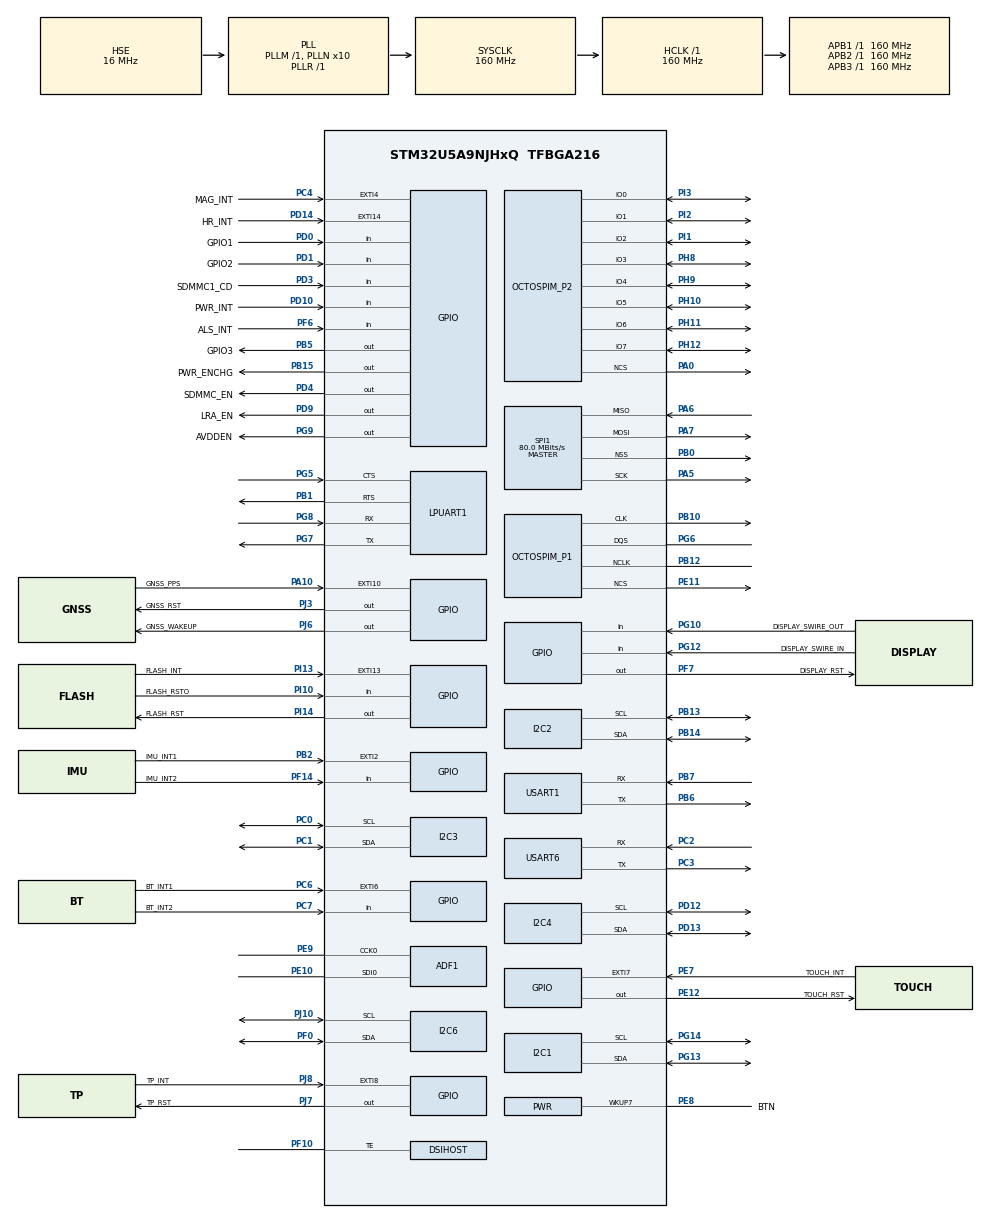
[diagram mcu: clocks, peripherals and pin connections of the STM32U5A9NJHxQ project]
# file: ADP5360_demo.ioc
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ADF1.MDF_SITF0_Mode_Display=MDF_SITF_NORMAL_SPI_MODE
CORTEX_M33_NS.userName=CORTEX_M33
DMA2D.ColorMode=DMA2D_OUTPUT_RGB888
DSIHOST.AutomaticClockLaneControl=DSI_AUTO_CLK_LANE_CTRL_DISABLE
DSIHOST.PHYFrequencyRange=DSI_DPHY_FRANGE_450MHZ_510MHZ
DSIHOST.PLLVCORange=DSI_DPHY_VCO_FRANGE_800MHZ_1GHZ
DSIHOST.StopWaitTime=10
DSI_CKN.Mode=DSIHost_Adapted_TE
DSI_CKN.Signal=DSIHOST_CKN
DSI_CKP.Mode=DSIHost_Adapted_TE
DSI_CKP.Signal=DSIHOST_CKP
DSI_D0N.Mode=DSIHost_Adapted_TE
DSI_D0N.Signal=DSIHOST_D0N
DSI_D0P.Mode=DSIHost_Adapted_TE
DSI_D0P.Signal=DSIHOST_D0P
DSI_D1N.Mode=DSIHost_Adapted_TE
DSI_D1N.Signal=DSIHOST_D1N
DSI_D1P.Mode=DSIHost_Adapted_TE
DSI_D1P.Signal=DSIHOST_D1P
I2C1.Timing=0x30909DEC
I2C2.Timing=0x30909DEC
I2C3.Timing=0x30909DEC
I2C4.Timing=0x30909DEC
I2C6.Timing=0x30909DEC
LTDC.ActiveH=416
LTDC.ActiveW=416
LTDC.Alpha_L0=255
LTDC.HBP=0
LTDC.HFP=0
LTDC.HSPolarity=LTDC_HSPOLARITY_AH
LTDC.HSync=1
LTDC.ImageHeight_L0=416
LTDC.ImageWidth_L0=416
LTDC.Layers=0
LTDC.VBP=0
LTDC.VFP=0
LTDC.VSPolarity=LTDC_VSPOLARITY_AH
LTDC.VSync=1
LTDC.WindowX1_L0=416
LTDC.WindowY1_L0=416
Mcu.Family=STM32U5
Mcu.Name=STM32U5A9NJHxQ
Mcu.Package=TFBGA216
Mcu.UserConstants=OLED_WIDTH,416;OLED_HEIGHT,416
NVIC.DMA2D_IRQn=true\:0\:0\:false\:false\:true\:true\:true\:true
NVIC.DSI_IRQn=true\:0\:0\:false\:false\:true\:true\:true\:true
NVIC.GFXMMU_IRQn=true\:0\:0\:false\:false\:true\:true\:true\:true
NVIC.GPU2D_ER_IRQn=true\:0\:0\:false\:false\:true\:false\:true\:true
NVIC.GPU2D_IRQn=true\:0\:0\:false\:false\:true\:false\:true\:true
NVIC.LTDC_IRQn=true\:0\:0\:false\:false\:true\:true\:true\:true
NVIC.PriorityGroup=NVIC_PRIORITYGROUP_4
NVIC.TIM6_IRQn=true\:15\:0\:false\:false\:true\:false\:true\:true
NVIC.TimeBase=TIM6_IRQn
NVIC.TimeBaseIP=TIM6
OCTOSPI1.ClockPrescaler=16
OCTOSPI1.DeviceSize=26
OCTOSPI1.DeviceType=SPI_DEVICE_FLASH
OCTOSPI1.MaxTran=16
OCTOSPI1.WrapSize=HAL_OSPI_WRAP_64_BYTES
PA0.Mode=OCTOSPI2_Port2_NCS
PA0.Signal=OCTOSPIM_P2_NCS
PA10.GPIO_Label=GNSS_PPS
PA10.Signal=GPXTI10
PA11.Signal=USB_OTG_HS_DM
PA12.Signal=USB_OTG_HS_DP
PA13\ (JTMS/SWDIO).Mode=Trace_Asynchronous_SW
PA13\ (JTMS/SWDIO).Signal=DEBUG_JTMS-SWDIO
PA14\ (JTCK/SWCLK).Mode=Trace_Asynchronous_SW
PA14\ (JTCK/SWCLK).Signal=DEBUG_JTCK-SWCLK
PA5.Mode=Full_Duplex_Master
PA5.Signal=SPI1_SCK
PA6.Mode=Full_Duplex_Master
PA6.Signal=SPI1_MISO
PA7.Mode=Full_Duplex_Master
PA7.Signal=SPI1_MOSI
PB0.Mode=NSS_Signal_Hard_Output
PB0.Signal=SPI1_NSS
PB1.Mode=CTS_RTS
PB1.Signal=LPUART1_RTS
PB10.Mode=O1_P1_CLK_MX
PB10.Signal=OCTOSPIM_P1_CLK
PB12.Mode=OCTOSPI1_Port1_NCLK_MX
PB12.Signal=OCTOSPIM_P1_NCLK
PB13.Mode=I2C
PB13.Signal=I2C2_SCL
PB14.Mode=I2C
PB14.Signal=I2C2_SDA
PB15.GPIO_Label=PWR_ENCHG
PB15.GPIO_PuPd=GPIO_PULLDOWN
PB15.Signal=GPIO_Output
PB2.GPIO_Label=IMU_INT1
PB2.Signal=GPXTI2
PB3\ (JTDO/TRACESWO).Mode=Trace_Asynchronous_SW
PB3\ (JTDO/TRACESWO).Signal=DEBUG_JTDO-SWO
PB5.GPIO_Label=GPIO3
PB5.GPIO_PuPd=GPIO_PULLDOWN
PB5.Signal=GPIO_Output
PB6.Mode=Asynchronous
PB6.Signal=USART1_TX
PB7.Mode=Asynchronous
PB7.Signal=USART1_RX
PB8.Signal=SDMMC1_CKIN
PC0.Mode=I2C
PC0.Signal=I2C3_SCL
PC1.Mode=I2C
PC1.Signal=I2C3_SDA
PC10.Signal=SDMMC1_D2
PC11.Signal=SDMMC1_D3
PC12.Signal=SDMMC1_CK
PC14-OSC32_IN\ (PC14).Mode=LSE-External-Oscillator
PC14-OSC32_IN\ (PC14).Signal=RCC_OSC32_IN
PC15-OSC32_OUT\ (PC15).Mode=LSE-External-Oscillator
PC15-OSC32_OUT\ (PC15).Signal=RCC_OSC32_OUT
PC2.Mode=Asynchronous
PC2.Signal=USART6_RX
PC3.Mode=Asynchronous
PC3.Signal=USART6_TX
PC4.GPIO_Label=MAG_INT
PC4.GPIO_ModeDefaultEXTI=GPIO_MODE_IT_FALLING
PC4.GPIO_PuPd=GPIO_PULLUP
PC4.Signal=GPXTI4
PC6.GPIO_Label=BT_INT1
PC6.GPIO_PuPd=GPIO_PULLDOWN
PC6.Signal=GPXTI6
PC7.GPIO_Label=BT_INT2
PC7.GPIO_PuPd=GPIO_PULLDOWN
PC7.Signal=GPIO_Input
PC8.Signal=SDMMC1_D0
PC9.Signal=SDMMC1_D1
PD0.GPIO_Label=GPIO1
PD0.GPIO_PuPd=GPIO_PULLDOWN
PD0.Signal=GPIO_Input
PD1.GPIO_Label=GPIO2
PD1.GPIO_PuPd=GPIO_PULLDOWN
PD1.Signal=GPIO_Input
PD10.GPIO_Label=PWR_INT
PD10.GPIO_PuPd=GPIO_PULLUP
PD10.Signal=GPIO_Input
PD12.Mode=I2C
PD12.Signal=I2C4_SCL
PD13.Mode=I2C
PD13.Signal=I2C4_SDA
PD14.GPIO_Label=HR_INT
PD14.GPIO_ModeDefaultEXTI=GPIO_MODE_IT_FALLING
PD14.GPIO_PuPd=GPIO_PULLUP
PD14.Signal=GPXTI14
PD2.Signal=SDMMC1_CMD
PD3.GPIO_Label=SDMMC1_CD
PD3.GPIO_PuPd=GPIO_PULLUP
PD3.Signal=GPIO_Input
PD4.GPIO_Label=SDMMC_EN
PD4.GPIO_ModeDefaultOutputPP=GPIO_MODE_OUTPUT_PP
PD4.GPIO_PuPd=GPIO_NOPULL
PD4.Signal=GPIO_Output
PD9.GPIO_Label=LRA_EN
PD9.GPIO_PuPd=GPIO_PULLDOWN
PD9.Signal=GPIO_Output
PE10.Mode=MOD_ADF_CCK
PE10.Signal=ADF1_SDI0
PE11.Mode=OCTOSPI1_Port1_NCS
PE11.Signal=OCTOSPIM_P1_NCS
PE12.GPIO_Label=TOUCH_RST
PE12.GPIO_PuPd=GPIO_PULLUP
PE12.Signal=GPIO_Output
PE7.GPIO_Label=TOUCH_INT
PE7.GPIO_ModeDefaultEXTI=GPIO_MODE_IT_FALLING
PE7.GPIO_PuPd=GPIO_PULLUP
PE7.Signal=GPXTI7
PE8.GPIO_Label=BTN
PE8.Mode=WakeUp7
PE8.Signal=PWR_WKUP7
PE9.Mode=MOD_MDF_CCK0
PE9.Signal=ADF1_CCK0
PF0.Mode=I2C
PF0.Signal=I2C6_SDA
PF10.Mode=DSIHost_Adapted_TE
PF10.Signal=DSIHOST_TE
PF14.GPIO_Label=IMU_INT2
PF14.Signal=GPIO_Input
PF6.GPIO_Label=ALS_INT
PF6.GPIO_PuPd=GPIO_PULLUP
PF6.Signal=GPIO_Input
PF7.GPIO_Label=DISPLAY_RST
PF7.GPIO_PuPd=GPIO_PULLUP
PF7.Signal=GPIO_Output
PG10.GPIO_Label=DISPLAY_SWIRE_OUT
PG10.Signal=GPIO_Input
PG12.GPIO_Label=DISPLAY_SWIRE_IN
PG12.Signal=GPIO_Input
PG13.Mode=I2C
PG13.Signal=I2C1_SDA
PG14.Mode=I2C
PG14.Signal=I2C1_SCL
PG5.Mode=CTS_RTS
PG5.Signal=LPUART1_CTS
PG6.Mode=OCTOSPI1_Port1_DQS_MX
PG6.Signal=OCTOSPIM_P1_DQS
PG7.Mode=Asynchronous
PG7.Signal=LPUART1_TX
PG8.Mode=Asynchronous
PG8.Signal=LPUART1_RX
PG9.GPIO_Label=AVDDEN
PG9.GPIO_PuPd=GPIO_PULLDOWN
PG9.Signal=GPIO_Output
PH0-OSC_IN\ (PH0).Mode=HSE-External-Oscillator
PH0-OSC_IN\ (PH0).Signal=RCC_OSC_IN
PH1-OSC_OUT\ (PH1).Mode=HSE-External-Oscillator
PH1-OSC_OUT\ (PH1).Signal=RCC_OSC_OUT
PH10.Mode=OCTOSPI1_IOH_Port2H_74_MX
PH10.Signal=OCTOSPIM_P2_IO5
PH11.Mode=OCTOSPI1_IOH_Port2H_74_MX
PH11.Signal=OCTOSPIM_P2_IO6
PH12.Mode=OCTOSPI1_IOH_Port2H_74_MX
PH12.Signal=OCTOSPIM_P2_IO7
PH8.Mode=OCTOSPI1_IOL_Port2L_30_MX
PH8.Signal=OCTOSPIM_P2_IO3
PH9.Mode=OCTOSPI1_IOH_Port2H_74_MX
PH9.Signal=OCTOSPIM_P2_IO4
PI1.Mode=OCTOSPI1_IOL_Port2L_30_MX
PI1.Signal=OCTOSPIM_P2_IO2
PI10.GPIO_Label=FLASH_RSTO
PI10.GPIO_PuPd=GPIO_PULLUP
PI10.Signal=GPIO_Input
PI13.GPIO_Label=FLASH_INT
PI13.GPIO_ModeDefaultEXTI=GPIO_MODE_IT_FALLING
PI13.GPIO_PuPd=GPIO_PULLUP
PI13.Signal=GPXTI13
PI14.GPIO_Label=FLASH_RST
PI14.GPIO_PuPd=GPIO_PULLUP
PI14.Signal=GPIO_Output
PI2.Mode=OCTOSPI1_IOL_Port2L_30_MX
PI2.Signal=OCTOSPIM_P2_IO1
PI3.Mode=OCTOSPI1_IOL_Port2L_30_MX
PI3.Signal=OCTOSPIM_P2_IO0
PJ10.Mode=I2C
PJ10.Signal=I2C6_SCL
PJ3.GPIO_Label=GNSS_RST
PJ3.GPIO_PuPd=GPIO_PULLUP
PJ3.Signal=GPIO_Output
PJ6.GPIO_Label=GNSS_WAKEUP
PJ6.Signal=GPIO_Output
PJ7.GPIO_Label=TP_RST
PJ7.GPIO_PuPd=GPIO_PULLUP
PJ7.Signal=GPIO_Output
PJ8.GPIO_Label=TP_INT
PJ8.GPIO_ModeDefaultEXTI=GPIO_MODE_IT_FALLING
PJ8.GPIO_PuPd=GPIO_PULLUP
PJ8.Signal=GPXTI8
PWR.PowerMode=PWR_SMPS_SUPPLY
ProjectManager.HeapSize=0x200
ProjectManager.StackSize=0x400
ProjectManager.TargetToolchain=STM32CubeIDE
RCC.ADCFreq_Value=16000000
RCC.AHBFreq_Value=160000000
RCC.APB1Freq_Value=160000000
RCC.APB1TimFreq_Value=160000000
RCC.APB2Freq_Value=160000000
RCC.APB2TimFreq_Value=160000000
RCC.APB3Freq_Value=160000000
RCC.CortexFreq_Value=160000000
RCC.EPOD_VALUE=16000000
RCC.EnableCSSLSE=true
RCC.EnbaleCSS=true
RCC.HCLKFreq_Value=160000000
RCC.HSE_VALUE=16000000
RCC.HSI48_VALUE=48000000
RCC.HSI_VALUE=16000000
RCC.LSIDIV_VALUE=32000
RCC.MSIClockRange=RCC_MSIRANGE_0
RCC.MSI_VALUE=48000000
RCC.PLL1R=1
RCC.PLL2N=20
RCC.PLL2Source=RCC_PLLSOURCE_HSE
RCC.PLL3N=10
RCC.PLL3Source=RCC_PLLSOURCE_HSE
RCC.PLLDSIIDF=DSI_PLL_IN_DIV4
RCC.PLLDSINDIV=125
RCC.PLLDSIODF=DSI_PLL_OUT_DIV2
RCC.PLLFRACN=0
RCC.PLLN=10
RCC.PLLSourceVirtual=RCC_PLLSOURCE_HSE
RCC.RTCClockSelection=RCC_RTCCLKSOURCE_LSE
RCC.SYSCLKFreq_VALUE=160000000
RCC.SYSCLKSource=RCC_SYSCLKSOURCE_PLLCLK
RCC.USBPHYCLockSelection=RCC_USBPHYCLKSOURCE_HSE
RCC.VCOOutputFreq_Value=160000000
RCC.VDD_VALUE=1.8
RTC.Date=1
SPI1.CalculateBaudRate=80.0 MBits/s
SPI1.Direction=SPI_DIRECTION_2LINES
SPI1.Mode=SPI_MODE_MASTER
SPI1.VirtualNSS=VM_NSSHARD
SPI1.VirtualType=VM_MASTER
STMicroelectronics.X-CUBE-TOUCHGFX.4.23.0.tgfx_custom_height=416
STMicroelectronics.X-CUBE-TOUCHGFX.4.23.0.tgfx_display_interface=disp_ltdc
STMicroelectronics.X-CUBE-TOUCHGFX.4.23.0.tgfx_hardware_accelerator=dma_2d
STMicroelectronics.X-CUBE-TOUCHGFX.4.23.0.tgfx_nemap_accelerator=gpu2d_enabled
STMicroelectronics.X-CUBE-TOUCHGFX.4.23.0.tgfx_pixel_format=ARGB8888\:32
STMicroelectronics.X-CUBE-TOUCHGFX.4.23.0_IsPackSelfContextualization=true
USART1.VirtualMode-Asynchronous=VM_ASYNC
USART6.VirtualMode-Asynchronous=VM_ASYNC
VP_CRC_VS_CRC.Mode=CRC_Activate
VP_DCACHE1_VS_DCACHE.Mode=DCACHE_Activate
VP_DCACHE2_VS_DCACHE.Mode=DCACHE_Activate
VP_DMA2D_VS_DMA2D.Mode=DMA2D_Activate
VP_GFXMMU_VS_GFXMMU.Mode=GFXMMU_Activate
VP_GPU2D_VS_GPU2D.Mode=GPU2D_Activate
VP_ICACHE_VS_ENABLE_ICACHE_MEMORY.Mode=Memoryregions
VP_ICACHE_VS_ICACHE.Mode=DefaultMode
VP_LPBAMQUEUE_VS_QUEUE.Mode=QUEUEMODE
VP_LPBAM_VS_SIG1.Mode=SmartRun
VP_LPBAM_VS_SIG4.Mode=LPDMA1
VP_LTDC_DSIMode.Mode=RGB888
VP_MEMORYMAP_VS_MEMORYMAP.Mode=CurAppReg
VP_OCTOSPI1_VS_hyperbus_mx.Mode=hyperbus_mode_mx
VP_OCTOSPI2_VS_hyperbus_mx.Mode=hyperbus_mode_mx
VP_OCTOSPI2_VS_ospi2_mx_p1_clk.Mode=O2_P1_CLK_MX
VP_OCTOSPI2_VS_ospi2_mx_p1_dqs.Mode=OCTOSPI2_Port1_DQS_MX
VP_OCTOSPI2_VS_ospi2_mx_p1_nclk.Mode=OCTOSPI2_Port1_NCLK_MX
VP_OCTOSPI2_VS_ospi2_mx_p2_30.Mode=OCTOSPI2_IOL_Port2L_30_MX
VP_OCTOSPI2_VS_ospi2_mx_p2_74.Mode=OCTOSPI2_IOH_Port2H_74_MX
VP_PWR_VS_LPOM.Mode=PowerOptimisation
VP_PWR_VS_SECSignals.Mode=Security/Privilege
VP_RTC_VS_RTC_Activate.Mode=RTC_Enabled
VP_RTC_VS_RTC_Calendar.Mode=RTC_Calendar
VP_SYS_VS_tim6.Mode=TIM6
board=custom

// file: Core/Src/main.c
/* USER CODE BEGIN Header */
/**
  ******************************************************************************
  * @file           : main.c
  * @brief          : Main program body
  ******************************************************************************
  * @attention
  *
  * Copyright (c) 2024 STMicroelectronics.
  * All rights reserved.
  *
  * This software is licensed under terms that can be found in the LICENSE file
  * in the root directory of this software component.
  * If no LICENSE file comes with this software, it is provided AS-IS.
  *
  ******************************************************************************
  */
/* USER CODE END Header */
#include "main.h"
#include "gfxmmu_lut.h"

/* USER CODE BEGIN Includes */
#include "ADP5360.h"
/* USER CODE END Includes */

MDF_HandleTypeDef AdfHandle0;
MDF_FilterConfigTypeDef AdfFilterConfig0;

CRC_HandleTypeDef hcrc;

DCACHE_HandleTypeDef hdcache1;
DCACHE_HandleTypeDef hdcache2;

DMA2D_HandleTypeDef hdma2d;

DSI_HandleTypeDef hdsi;

GFXMMU_HandleTypeDef hgfxmmu;

GPU2D_HandleTypeDef hgpu2d;

I2C_HandleTypeDef hi2c1;
I2C_HandleTypeDef hi2c2;
I2C_HandleTypeDef hi2c3;
I2C_HandleTypeDef hi2c4;
I2C_HandleTypeDef hi2c6;

UART_HandleTypeDef hlpuart1;
UART_HandleTypeDef huart1;
UART_HandleTypeDef huart6;

LTDC_HandleTypeDef hltdc;

OSPI_HandleTypeDef hospi1;
OSPI_HandleTypeDef hospi2;

RTC_HandleTypeDef hrtc;

SPI_HandleTypeDef hspi1;

/* USER CODE BEGIN PV */

ADP5360_HandleTypeDef hadp5360;

/* USER CODE END PV */

void SystemClock_Config(void);
static void SystemPower_Config(void);
static void MX_GPIO_Init(void);
static void MX_DCACHE1_Init(void);
static void MX_DCACHE2_Init(void);
static void MX_ICACHE_Init(void);
static void MX_LPUART1_UART_Init(void);
static void MX_OCTOSPI1_Init(void);
static void MX_CRC_Init(void);
static void MX_DMA2D_Init(void);
static void MX_DSIHOST_DSI_Init(void);
static void MX_GFXMMU_Init(void);
static void MX_GPU2D_Init(void);
static void MX_LTDC_Init(void);
static void MX_RTC_Init(void);
static void MX_OCTOSPI2_Init(void);
static void MX_ADF1_Init(void);
static void MX_I2C1_Init(void);
static void MX_I2C2_Init(void);
static void MX_I2C4_Init(void);
static void MX_I2C6_Init(void);
static void MX_USART1_UART_Init(void);
static void MX_USART6_UART_Init(void);
static void MX_SPI1_Init(void);
static void MX_I2C3_Init(void);

int main(void)
{

  /* MCU Configuration--------------------------------------------------------*/

  /* Reset of all peripherals, Initializes the Flash interface and the Systick. */
  HAL_Init();

  /* Configure the system clock */
  SystemClock_Config();

  /* Configure the System Power */
  SystemPower_Config();

  /* Initialize all configured peripherals */
  MX_GPIO_Init();
  MX_DCACHE1_Init();
  MX_DCACHE2_Init();
  MX_ICACHE_Init();
  MX_LPUART1_UART_Init();
  MX_OCTOSPI1_Init();
  MX_CRC_Init();
  MX_DMA2D_Init();
  MX_DSIHOST_DSI_Init();
  MX_GFXMMU_Init();
  MX_GPU2D_Init();
  MX_LTDC_Init();
  MX_RTC_Init();
  MX_OCTOSPI2_Init();
  MX_ADF1_Init();
  MX_I2C1_Init();
  MX_I2C2_Init();
  MX_I2C4_Init();
  MX_I2C6_Init();
  MX_USART1_UART_Init();
  MX_USART6_UART_Init();
  MX_SPI1_Init();
  MX_I2C3_Init();

  /* USER CODE BEGIN 2 */
  ADP5360_Init(&hadp5360, &hi2c2);
  ADP5360_EnableMRShipmentMode(&hadp5360);
  ADP5360_EnableBuckBoost(&hadp5360);
  /* USER CODE END 2 */

  /* Infinite loop */
  while (1)
  {

  }
}

void SystemClock_Config(void)
{
  RCC_OscInitTypeDef RCC_OscInitStruct = {0};
  RCC_ClkInitTypeDef RCC_ClkInitStruct = {0};

  /** Configure the main internal regulator output voltage
  */
  if (HAL_PWREx_ControlVoltageScaling(PWR_REGULATOR_VOLTAGE_SCALE1) != HAL_OK)
  {
    Error_Handler();
  }

  /** Configure LSE Drive Capability
  */
  HAL_PWR_EnableBkUpAccess();
  __HAL_RCC_LSEDRIVE_CONFIG(RCC_LSEDRIVE_LOW);

  /** Initializes the CPU, AHB and APB buses clocks
  */
  RCC_OscInitStruct.OscillatorType = RCC_OSCILLATORTYPE_HSE|RCC_OSCILLATORTYPE_LSE;
  RCC_OscInitStruct.HSEState = RCC_HSE_ON;
  RCC_OscInitStruct.LSEState = RCC_LSE_ON;
  RCC_OscInitStruct.PLL.PLLState = RCC_PLL_ON;
  RCC_OscInitStruct.PLL.PLLSource = RCC_PLLSOURCE_HSE;
  RCC_OscInitStruct.PLL.PLLMBOOST = RCC_PLLMBOOST_DIV1;
  RCC_OscInitStruct.PLL.PLLM = 1;
  RCC_OscInitStruct.PLL.PLLN = 10;
  RCC_OscInitStruct.PLL.PLLP = 2;
  RCC_OscInitStruct.PLL.PLLQ = 2;
  RCC_OscInitStruct.PLL.PLLR = 1;
  RCC_OscInitStruct.PLL.PLLRGE = RCC_PLLVCIRANGE_1;
  RCC_OscInitStruct.PLL.PLLFRACN = 0;
  if (HAL_RCC_OscConfig(&RCC_OscInitStruct) != HAL_OK)
  {
    Error_Handler();
  }

  /** Initializes the CPU, AHB and APB buses clocks
  */
  RCC_ClkInitStruct.ClockType = RCC_CLOCKTYPE_HCLK|RCC_CLOCKTYPE_SYSCLK
                              |RCC_CLOCKTYPE_PCLK1|RCC_CLOCKTYPE_PCLK2
                              |RCC_CLOCKTYPE_PCLK3;
  RCC_ClkInitStruct.SYSCLKSource = RCC_SYSCLKSOURCE_PLLCLK;
  RCC_ClkInitStruct.AHBCLKDivider = RCC_SYSCLK_DIV1;
  RCC_ClkInitStruct.APB1CLKDivider = RCC_HCLK_DIV1;
  RCC_ClkInitStruct.APB2CLKDivider = RCC_HCLK_DIV1;
  RCC_ClkInitStruct.APB3CLKDivider = RCC_HCLK_DIV1;

  if (HAL_RCC_ClockConfig(&RCC_ClkInitStruct, FLASH_LATENCY_4) != HAL_OK)
  {
    Error_Handler();
  }

  /** Enables the Clock Security System
  */
  HAL_RCC_EnableCSS();

  /** Enables the Clock Security System
  */
  HAL_RCCEx_EnableLSECSS();
}

/**
  * @brief Power Configuration
  * @retval None
  */
static void SystemPower_Config(void)
{
  HAL_PWREx_EnableVddIO2();

  /*
   * Switch to SMPS regulator instead of LDO
   */
  if (HAL_PWREx_ConfigSupply(PWR_SMPS_SUPPLY) != HAL_OK)
  {
    Error_Handler();
  }
}

static void MX_ADF1_Init(void)
{

  /**
    AdfHandle0 structure initialization and HAL_MDF_Init function call
  */
  AdfHandle0.Instance = ADF1_Filter0;
  AdfHandle0.Init.CommonParam.ProcClockDivider = 1;
  AdfHandle0.Init.CommonParam.OutputClock.Activation = DISABLE;
  AdfHandle0.Init.SerialInterface.Activation = ENABLE;
  AdfHandle0.Init.SerialInterface.Mode = MDF_SITF_NORMAL_SPI_MODE;
  AdfHandle0.Init.SerialInterface.ClockSource = MDF_SITF_CCK0_SOURCE;
  AdfHandle0.Init.SerialInterface.Threshold = 4;
  AdfHandle0.Init.FilterBistream = MDF_BITSTREAM0_FALLING;
  if (HAL_MDF_Init(&AdfHandle0) != HAL_OK)
  {
    Error_Handler();
  }

  /**
    AdfFilterConfig0 structure initialization

    WARNING : only structure is filled, no specific init function call for filter
  */
  AdfFilterConfig0.DataSource = MDF_DATA_SOURCE_BSMX;
  AdfFilterConfig0.Delay = 0;
  AdfFilterConfig0.CicMode = MDF_ONE_FILTER_SINC4;
  AdfFilterConfig0.DecimationRatio = 2;
  AdfFilterConfig0.Gain = 0;
  AdfFilterConfig0.ReshapeFilter.Activation = DISABLE;
  AdfFilterConfig0.HighPassFilter.Activation = DISABLE;
  AdfFilterConfig0.SoundActivity.Activation = DISABLE;
  AdfFilterConfig0.AcquisitionMode = MDF_MODE_ASYNC_CONT;
  AdfFilterConfig0.FifoThreshold = MDF_FIFO_THRESHOLD_NOT_EMPTY;
  AdfFilterConfig0.DiscardSamples = 0;

}

static void MX_CRC_Init(void)
{

  hcrc.Instance = CRC;
  hcrc.Init.DefaultPolynomialUse = DEFAULT_POLYNOMIAL_ENABLE;
  hcrc.Init.DefaultInitValueUse = DEFAULT_INIT_VALUE_ENABLE;
  hcrc.Init.InputDataInversionMode = CRC_INPUTDATA_INVERSION_NONE;
  hcrc.Init.OutputDataInversionMode = CRC_OUTPUTDATA_INVERSION_DISABLE;
  hcrc.InputDataFormat = CRC_INPUTDATA_FORMAT_BYTES;
  if (HAL_CRC_Init(&hcrc) != HAL_OK)
  {
    Error_Handler();
  }

}

static void MX_DCACHE1_Init(void)
{

  hdcache1.Instance = DCACHE1;
  hdcache1.Init.ReadBurstType = DCACHE_READ_BURST_WRAP;
  if (HAL_DCACHE_Init(&hdcache1) != HAL_OK)
  {
    Error_Handler();
  }

}

static void MX_DCACHE2_Init(void)
{

  hdcache2.Instance = DCACHE2;
  hdcache2.Init.ReadBurstType = DCACHE_READ_BURST_WRAP;
  if (HAL_DCACHE_Init(&hdcache2) != HAL_OK)
  {
    Error_Handler();
  }

}

static void MX_DMA2D_Init(void)
{

  hdma2d.Instance = DMA2D;
  hdma2d.Init.Mode = DMA2D_M2M;
  hdma2d.Init.ColorMode = DMA2D_OUTPUT_RGB888;
  hdma2d.Init.OutputOffset = 0;
  hdma2d.Init.BytesSwap = DMA2D_BYTES_REGULAR;
  hdma2d.Init.LineOffsetMode = DMA2D_LOM_PIXELS;
  hdma2d.LayerCfg[1].InputOffset = 0;
  hdma2d.LayerCfg[1].InputColorMode = DMA2D_INPUT_RGB888;
  hdma2d.LayerCfg[1].AlphaMode = DMA2D_NO_MODIF_ALPHA;
  hdma2d.LayerCfg[1].InputAlpha = 0;
  hdma2d.LayerCfg[1].AlphaInverted = DMA2D_REGULAR_ALPHA;
  hdma2d.LayerCfg[1].RedBlueSwap = DMA2D_RB_REGULAR;
  if (HAL_DMA2D_Init(&hdma2d) != HAL_OK)
  {
    Error_Handler();
  }
  if (HAL_DMA2D_ConfigLayer(&hdma2d, 1) != HAL_OK)
  {
    Error_Handler();
  }

}

static void MX_DSIHOST_DSI_Init(void)
{

  DSI_PLLInitTypeDef PLLInit = {0};
  DSI_HOST_TimeoutTypeDef HostTimeouts = {0};
  DSI_PHY_TimerTypeDef PhyTimings = {0};
  DSI_LPCmdTypeDef LPCmd = {0};
  DSI_CmdCfgTypeDef CmdCfg = {0};

  hdsi.Instance = DSI;
  hdsi.Init.AutomaticClockLaneControl = DSI_AUTO_CLK_LANE_CTRL_DISABLE;
  hdsi.Init.TXEscapeCkdiv = 4;
  hdsi.Init.NumberOfLanes = DSI_ONE_DATA_LANE;
  hdsi.Init.PHYFrequencyRange = DSI_DPHY_FRANGE_450MHZ_510MHZ;
  hdsi.Init.PHYLowPowerOffset = PHY_LP_OFFSSET_0_CLKP;
  PLLInit.PLLNDIV = 125;
  PLLInit.PLLIDF = DSI_PLL_IN_DIV4;
  PLLInit.PLLODF = DSI_PLL_OUT_DIV2;
  PLLInit.PLLVCORange = DSI_DPHY_VCO_FRANGE_800MHZ_1GHZ;
  PLLInit.PLLChargePump = DSI_PLL_CHARGE_PUMP_2000HZ_4400HZ;
  PLLInit.PLLTuning = DSI_PLL_LOOP_FILTER_2000HZ_4400HZ;
  if (HAL_DSI_Init(&hdsi, &PLLInit) != HAL_OK)
  {
    Error_Handler();
  }
  HostTimeouts.TimeoutCkdiv = 1;
  HostTimeouts.HighSpeedTransmissionTimeout = 0;
  HostTimeouts.LowPowerReceptionTimeout = 0;
  HostTimeouts.HighSpeedReadTimeout = 0;
  HostTimeouts.LowPowerReadTimeout = 0;
  HostTimeouts.HighSpeedWriteTimeout = 0;
  HostTimeouts.HighSpeedWritePrespMode = DSI_HS_PM_DISABLE;
  HostTimeouts.LowPowerWriteTimeout = 0;
  HostTimeouts.BTATimeout = 0;
  if (HAL_DSI_ConfigHostTimeouts(&hdsi, &HostTimeouts) != HAL_OK)
  {
    Error_Handler();
  }
  PhyTimings.ClockLaneHS2LPTime = 10;
  PhyTimings.ClockLaneLP2HSTime = 0;
  PhyTimings.DataLaneHS2LPTime = 0;
  PhyTimings.DataLaneLP2HSTime = 0;
  PhyTimings.DataLaneMaxReadTime = 0;
  PhyTimings.StopWaitTime = 10;
  if (HAL_DSI_ConfigPhyTimer(&hdsi, &PhyTimings) != HAL_OK)
  {
    Error_Handler();
  }
  if (HAL_DSI_ConfigFlowControl(&hdsi, DSI_FLOW_CONTROL_BTA) != HAL_OK)
  {
    Error_Handler();
  }
  if (HAL_DSI_ConfigErrorMonitor(&hdsi, HAL_DSI_ERROR_NONE) != HAL_OK)
  {
    Error_Handler();
  }
  LPCmd.LPGenShortWriteNoP = DSI_LP_GSW0P_DISABLE;
  LPCmd.LPGenShortWriteOneP = DSI_LP_GSW1P_DISABLE;
  LPCmd.LPGenShortWriteTwoP = DSI_LP_GSW2P_DISABLE;
  LPCmd.LPGenShortReadNoP = DSI_LP_GSR0P_DISABLE;
  LPCmd.LPGenShortReadOneP = DSI_LP_GSR1P_DISABLE;
  LPCmd.LPGenShortReadTwoP = DSI_LP_GSR2P_DISABLE;
  LPCmd.LPGenLongWrite = DSI_LP_GLW_DISABLE;
  LPCmd.LPDcsShortWriteNoP = DSI_LP_DSW0P_DISABLE;
  LPCmd.LPDcsShortWriteOneP = DSI_LP_DSW1P_DISABLE;
  LPCmd.LPDcsShortReadNoP = DSI_LP_DSR0P_DISABLE;
  LPCmd.LPDcsLongWrite = DSI_LP_DLW_DISABLE;
  LPCmd.LPMaxReadPacket = DSI_LP_MRDP_DISABLE;
  LPCmd.AcknowledgeRequest = DSI_ACKNOWLEDGE_DISABLE;
  if (HAL_DSI_ConfigCommand(&hdsi, &LPCmd) != HAL_OK)
  {
    Error_Handler();
  }
  CmdCfg.ColorCoding = DSI_RGB888;
  CmdCfg.CommandSize = 416;
  CmdCfg.TearingEffectSource = DSI_TE_EXTERNAL;
  CmdCfg.TearingEffectPolarity = DSI_TE_RISING_EDGE;
  CmdCfg.HSPolarity = DSI_HSYNC_ACTIVE_HIGH;
  CmdCfg.VSPolarity = DSI_VSYNC_ACTIVE_HIGH;
  CmdCfg.DEPolarity = DSI_DATA_ENABLE_ACTIVE_HIGH;
  CmdCfg.VSyncPol = DSI_VSYNC_RISING;
  CmdCfg.AutomaticRefresh = DSI_AR_ENABLE;
  CmdCfg.TEAcknowledgeRequest = DSI_TE_ACKNOWLEDGE_DISABLE;
  if (HAL_DSI_ConfigAdaptedCommandMode(&hdsi, &CmdCfg) != HAL_OK)
  {
    Error_Handler();
  }
  if (HAL_DSI_SetGenericVCID(&hdsi, 0) != HAL_OK)
  {
    Error_Handler();
  }

}

static void MX_GFXMMU_Init(void)
{

  hgfxmmu.Instance = GFXMMU;
  hgfxmmu.Init.BlocksPerLine = GFXMMU_192BLOCKS;
  hgfxmmu.Init.DefaultValue = 0;
  hgfxmmu.Init.Buffers.Buf0Address = 0;
  hgfxmmu.Init.Buffers.Buf1Address = 0;
  hgfxmmu.Init.Buffers.Buf2Address = 0;
  hgfxmmu.Init.Buffers.Buf3Address = 0;
  hgfxmmu.Init.CachePrefetch.Activation = ENABLE;
  hgfxmmu.Init.CachePrefetch.CacheLock = GFXMMU_CACHE_LOCK_ENABLE;
  hgfxmmu.Init.CachePrefetch.CacheLockBuffer = GFXMMU_CACHE_LOCK_BUFFER0;
  hgfxmmu.Init.CachePrefetch.CacheForce = GFXMMU_CACHE_FORCE_ENABLE;
  hgfxmmu.Init.CachePrefetch.OutterBufferability = GFXMMU_OUTTER_BUFFERABILITY_ENABLE;
  hgfxmmu.Init.CachePrefetch.OutterCachability = GFXMMU_OUTTER_CACHABILITY_ENABLE;
  hgfxmmu.Init.CachePrefetch.Prefetch = GFXMMU_PREFETCH_ENABLE;
  hgfxmmu.Init.Interrupts.Activation = ENABLE;
  if (HAL_GFXMMU_Init(&hgfxmmu) != HAL_OK)
  {
    Error_Handler();
  }
  if (HAL_GFXMMU_ConfigLut(&hgfxmmu, GFXMMU_LUT_FIRST, GFXMMU_LUT_SIZE, (uint32_t)gfxmmu_lut_config) != HAL_OK)
  {
    Error_Handler();
  }

}

static void MX_GPU2D_Init(void)
{

  hgpu2d.Instance = GPU2D;
  if (HAL_GPU2D_Init(&hgpu2d) != HAL_OK)
  {
    Error_Handler();
  }

}

static void MX_I2C1_Init(void)
{

  hi2c1.Instance = I2C1;
  hi2c1.Init.Timing = 0x30909DEC;
  hi2c1.Init.OwnAddress1 = 0;
  hi2c1.Init.AddressingMode = I2C_ADDRESSINGMODE_7BIT;
  hi2c1.Init.DualAddressMode = I2C_DUALADDRESS_DISABLE;
  hi2c1.Init.OwnAddress2 = 0;
  hi2c1.Init.OwnAddress2Masks = I2C_OA2_NOMASK;
  hi2c1.Init.GeneralCallMode = I2C_GENERALCALL_DISABLE;
  hi2c1.Init.NoStretchMode = I2C_NOSTRETCH_DISABLE;
  if (HAL_I2C_Init(&hi2c1) != HAL_OK)
  {
    Error_Handler();
  }

  /** Configure Analogue filter
  */
  if (HAL_I2CEx_ConfigAnalogFilter(&hi2c1, I2C_ANALOGFILTER_ENABLE) != HAL_OK)
  {
    Error_Handler();
  }

  /** Configure Digital filter
  */
  if (HAL_I2CEx_ConfigDigitalFilter(&hi2c1, 0) != HAL_OK)
  {
    Error_Handler();
  }

}

static void MX_I2C2_Init(void)
{

  hi2c2.Instance = I2C2;
  hi2c2.Init.Timing = 0x30909DEC;
  hi2c2.Init.OwnAddress1 = 0;
  hi2c2.Init.AddressingMode = I2C_ADDRESSINGMODE_7BIT;
  hi2c2.Init.DualAddressMode = I2C_DUALADDRESS_DISABLE;
  hi2c2.Init.OwnAddress2 = 0;
  hi2c2.Init.OwnAddress2Masks = I2C_OA2_NOMASK;
  hi2c2.Init.GeneralCallMode = I2C_GENERALCALL_DISABLE;
  hi2c2.Init.NoStretchMode = I2C_NOSTRETCH_DISABLE;
  if (HAL_I2C_Init(&hi2c2) != HAL_OK)
  {
    Error_Handler();
  }

  /** Configure Analogue filter
  */
  if (HAL_I2CEx_ConfigAnalogFilter(&hi2c2, I2C_ANALOGFILTER_ENABLE) != HAL_OK)
  {
    Error_Handler();
  }

  /** Configure Digital filter
  */
  if (HAL_I2CEx_ConfigDigitalFilter(&hi2c2, 0) != HAL_OK)
  {
    Error_Handler();
  }

}

static void MX_I2C3_Init(void)
{

  hi2c3.Instance = I2C3;
  hi2c3.Init.Timing = 0x30909DEC;
  hi2c3.Init.OwnAddress1 = 0;
  hi2c3.Init.AddressingMode = I2C_ADDRESSINGMODE_7BIT;
  hi2c3.Init.DualAddressMode = I2C_DUALADDRESS_DISABLE;
  hi2c3.Init.OwnAddress2 = 0;
  hi2c3.Init.OwnAddress2Masks = I2C_OA2_NOMASK;
  hi2c3.Init.GeneralCallMode = I2C_GENERALCALL_DISABLE;
  hi2c3.Init.NoStretchMode = I2C_NOSTRETCH_DISABLE;
  if (HAL_I2C_Init(&hi2c3) != HAL_OK)
  {
    Error_Handler();
  }

  /** Configure Analogue filter
  */
  if (HAL_I2CEx_ConfigAnalogFilter(&hi2c3, I2C_ANALOGFILTER_ENABLE) != HAL_OK)
  {
    Error_Handler();
  }

  /** Configure Digital filter
  */
  if (HAL_I2CEx_ConfigDigitalFilter(&hi2c3, 0) != HAL_OK)
  {
    Error_Handler();
  }

}

static void MX_I2C4_Init(void)
{

  hi2c4.Instance = I2C4;
  hi2c4.Init.Timing = 0x30909DEC;
  hi2c4.Init.OwnAddress1 = 0;
  hi2c4.Init.AddressingMode = I2C_ADDRESSINGMODE_7BIT;
  hi2c4.Init.DualAddressMode = I2C_DUALADDRESS_DISABLE;
  hi2c4.Init.OwnAddress2 = 0;
  hi2c4.Init.OwnAddress2Masks = I2C_OA2_NOMASK;
  hi2c4.Init.GeneralCallMode = I2C_GENERALCALL_DISABLE;
  hi2c4.Init.NoStretchMode = I2C_NOSTRETCH_DISABLE;
  if (HAL_I2C_Init(&hi2c4) != HAL_OK)
  {
    Error_Handler();
  }

  /** Configure Analogue filter
  */
  if (HAL_I2CEx_ConfigAnalogFilter(&hi2c4, I2C_ANALOGFILTER_ENABLE) != HAL_OK)
  {
    Error_Handler();
  }

  /** Configure Digital filter
  */
  if (HAL_I2CEx_ConfigDigitalFilter(&hi2c4, 0) != HAL_OK)
  {
    Error_Handler();
  }

}

static void MX_I2C6_Init(void)
{

  hi2c6.Instance = I2C6;
  hi2c6.Init.Timing = 0x30909DEC;
  hi2c6.Init.OwnAddress1 = 0;
  hi2c6.Init.AddressingMode = I2C_ADDRESSINGMODE_7BIT;
  hi2c6.Init.DualAddressMode = I2C_DUALADDRESS_DISABLE;
  hi2c6.Init.OwnAddress2 = 0;
  hi2c6.Init.OwnAddress2Masks = I2C_OA2_NOMASK;
  hi2c6.Init.GeneralCallMode = I2C_GENERALCALL_DISABLE;
  hi2c6.Init.NoStretchMode = I2C_NOSTRETCH_DISABLE;
  if (HAL_I2C_Init(&hi2c6) != HAL_OK)
  {
    Error_Handler();
  }

  /** Configure Analogue filter
  */
  if (HAL_I2CEx_ConfigAnalogFilter(&hi2c6, I2C_ANALOGFILTER_ENABLE) != HAL_OK)
  {
    Error_Handler();
  }

  /** Configure Digital filter
  */
  if (HAL_I2CEx_ConfigDigitalFilter(&hi2c6, 0) != HAL_OK)
  {
    Error_Handler();
  }

}

static void MX_ICACHE_Init(void)
{

  ICACHE_RegionConfigTypeDef pRegionConfig = {0};

  /** Configure and enable a region for memory remapping.
  */
  if (HAL_ICACHE_Disable() != HAL_OK)
  {
    Error_Handler();
  }
  pRegionConfig.BaseAddress = 0x10000000;
  pRegionConfig.RemapAddress = 0x60000000;
  pRegionConfig.Size = ICACHE_REGIONSIZE_2MB;
  pRegionConfig.TrafficRoute = ICACHE_MASTER1_PORT;
  pRegionConfig.OutputBurstType = ICACHE_OUTPUT_BURST_WRAP;
  if (HAL_ICACHE_EnableRemapRegion(_NULL, &pRegionConfig) != HAL_OK)
  {
    Error_Handler();
  }

  /** Enable instruction cache (default 2-ways set associative cache)
  */
  if (HAL_ICACHE_Enable() != HAL_OK)
  {
    Error_Handler();
  }

}

static void MX_LPUART1_UART_Init(void)
{

  hlpuart1.Instance = LPUART1;
  hlpuart1.Init.BaudRate = 209700;
  hlpuart1.Init.WordLength = UART_WORDLENGTH_8B;
  hlpuart1.Init.StopBits = UART_STOPBITS_1;
  hlpuart1.Init.Parity = UART_PARITY_NONE;
  hlpuart1.Init.Mode = UART_MODE_TX_RX;
  hlpuart1.Init.HwFlowCtl = UART_HWCONTROL_RTS_CTS;
  hlpuart1.Init.OneBitSampling = UART_ONE_BIT_SAMPLE_DISABLE;
  hlpuart1.AdvancedInit.AdvFeatureInit = UART_ADVFEATURE_NO_INIT;
  hlpuart1.FifoMode = UART_FIFOMODE_DISABLE;
  if (HAL_UART_Init(&hlpuart1) != HAL_OK)
  {
    Error_Handler();
  }
  if (HAL_UARTEx_SetTxFifoThreshold(&hlpuart1, UART_TXFIFO_THRESHOLD_1_8) != HAL_OK)
  {
    Error_Handler();
  }
  if (HAL_UARTEx_SetRxFifoThreshold(&hlpuart1, UART_RXFIFO_THRESHOLD_1_8) != HAL_OK)
  {
    Error_Handler();
  }
  if (HAL_UARTEx_DisableFifoMode(&hlpuart1) != HAL_OK)
  {
    Error_Handler();
  }

}

static void MX_USART1_UART_Init(void)
{

  huart1.Instance = USART1;
  huart1.Init.BaudRate = 115200;
  huart1.Init.WordLength = UART_WORDLENGTH_8B;
  huart1.Init.StopBits = UART_STOPBITS_1;
  huart1.Init.Parity = UART_PARITY_NONE;
  huart1.Init.Mode = UART_MODE_TX_RX;
  huart1.Init.HwFlowCtl = UART_HWCONTROL_NONE;
  huart1.Init.OverSampling = UART_OVERSAMPLING_16;
  huart1.Init.OneBitSampling = UART_ONE_BIT_SAMPLE_DISABLE;
  huart1.Init.ClockPrescaler = UART_PRESCALER_DIV1;
  huart1.AdvancedInit.AdvFeatureInit = UART_ADVFEATURE_NO_INIT;
  if (HAL_UART_Init(&huart1) != HAL_OK)
  {
    Error_Handler();
  }
  if (HAL_UARTEx_SetTxFifoThreshold(&huart1, UART_TXFIFO_THRESHOLD_1_8) != HAL_OK)
  {
    Error_Handler();
  }
  if (HAL_UARTEx_SetRxFifoThreshold(&huart1, UART_RXFIFO_THRESHOLD_1_8) != HAL_OK)
  {
    Error_Handler();
  }
  if (HAL_UARTEx_DisableFifoMode(&huart1) != HAL_OK)
  {
    Error_Handler();
  }

}

static void MX_USART6_UART_Init(void)
{

  huart6.Instance = USART6;
  huart6.Init.BaudRate = 115200;
  huart6.Init.WordLength = UART_WORDLENGTH_8B;
  huart6.Init.StopBits = UART_STOPBITS_1;
  huart6.Init.Parity = UART_PARITY_NONE;
  huart6.Init.Mode = UART_MODE_TX_RX;
  huart6.Init.HwFlowCtl = UART_HWCONTROL_NONE;
  huart6.Init.OverSampling = UART_OVERSAMPLING_16;
  huart6.Init.OneBitSampling = UART_ONE_BIT_SAMPLE_DISABLE;
  huart6.Init.ClockPrescaler = UART_PRESCALER_DIV1;
  huart6.AdvancedInit.AdvFeatureInit = UART_ADVFEATURE_NO_INIT;
  if (HAL_UART_Init(&huart6) != HAL_OK)
  {
    Error_Handler();
  }
  if (HAL_UARTEx_SetTxFifoThreshold(&huart6, UART_TXFIFO_THRESHOLD_1_8) != HAL_OK)
  {
    Error_Handler();
  }
  if (HAL_UARTEx_SetRxFifoThreshold(&huart6, UART_RXFIFO_THRESHOLD_1_8) != HAL_OK)
  {
    Error_Handler();
  }
  if (HAL_UARTEx_DisableFifoMode(&huart6) != HAL_OK)
  {
    Error_Handler();
  }

}

static void MX_LTDC_Init(void)
{

  LTDC_LayerCfgTypeDef pLayerCfg = {0};

  hltdc.Instance = LTDC;
  hltdc.Init.HSPolarity = LTDC_HSPOLARITY_AH;
  hltdc.Init.VSPolarity = LTDC_VSPOLARITY_AH;
  hltdc.Init.DEPolarity = LTDC_DEPOLARITY_AL;
  hltdc.Init.PCPolarity = LTDC_PCPOLARITY_IPC;
  hltdc.Init.HorizontalSync = 0;
  hltdc.Init.VerticalSync = 0;
  hltdc.Init.AccumulatedHBP = 0;
  hltdc.Init.AccumulatedVBP = 0;
  hltdc.Init.AccumulatedActiveW = 416;
  hltdc.Init.AccumulatedActiveH = 416;
  hltdc.Init.TotalWidth = 416;
  hltdc.Init.TotalHeigh = 416;
  hltdc.Init.Backcolor.Blue = 0;
  hltdc.Init.Backcolor.Green = 0;
  hltdc.Init.Backcolor.Red = 0;
  if (HAL_LTDC_Init(&hltdc) != HAL_OK)
  {
    Error_Handler();
  }
  pLayerCfg.WindowX0 = 0;
  pLayerCfg.WindowX1 = 416;
  pLayerCfg.WindowY0 = 0;
  pLayerCfg.WindowY1 = 416;
  pLayerCfg.PixelFormat = LTDC_PIXEL_FORMAT_ARGB8888;
  pLayerCfg.Alpha = 255;
  pLayerCfg.Alpha0 = 0;
  pLayerCfg.BlendingFactor1 = LTDC_BLENDING_FACTOR1_CA;
  pLayerCfg.BlendingFactor2 = LTDC_BLENDING_FACTOR2_CA;
  pLayerCfg.FBStartAdress = GFXMMU_VIRTUAL_BUFFER0_BASE;
  pLayerCfg.ImageWidth = 416;
  pLayerCfg.ImageHeight = 416;
  pLayerCfg.Backcolor.Blue = 0;
  pLayerCfg.Backcolor.Green = 0;
  pLayerCfg.Backcolor.Red = 0;
  if (HAL_LTDC_ConfigLayer(&hltdc, &pLayerCfg, 0) != HAL_OK)
  {
    Error_Handler();
  }

}

static void MX_OCTOSPI1_Init(void)
{

  OSPIM_CfgTypeDef sOspiManagerCfg = {0};
  OSPI_HyperbusCfgTypeDef sHyperBusCfg = {0};
  HAL_OSPI_DLYB_CfgTypeDef HAL_OSPI_DLYB_Cfg_Struct = {0};

  /* OCTOSPI1 parameter configuration*/
  hospi1.Instance = OCTOSPI1;
  hospi1.Init.FifoThreshold = 1;
  hospi1.Init.DualQuad = HAL_OSPI_DUALQUAD_DISABLE;
  hospi1.Init.MemoryType = HAL_OSPI_MEMTYPE_HYPERBUS;
  hospi1.Init.DeviceSize = 26;
  hospi1.Init.ChipSelectHighTime = 1;
  hospi1.Init.FreeRunningClock = HAL_OSPI_FREERUNCLK_DISABLE;
  hospi1.Init.ClockMode = HAL_OSPI_CLOCK_MODE_0;
  hospi1.Init.WrapSize = HAL_OSPI_WRAP_64_BYTES;
  hospi1.Init.ClockPrescaler = 16;
  hospi1.Init.SampleShifting = HAL_OSPI_SAMPLE_SHIFTING_NONE;
  hospi1.Init.DelayHoldQuarterCycle = HAL_OSPI_DHQC_DISABLE;
  hospi1.Init.ChipSelectBoundary = 0;
  hospi1.Init.DelayBlockBypass = HAL_OSPI_DELAY_BLOCK_BYPASSED;
  hospi1.Init.MaxTran = 16;
  hospi1.Init.Refresh = 0;
  if (HAL_OSPI_Init(&hospi1) != HAL_OK)
  {
    Error_Handler();
  }
  sOspiManagerCfg.ClkPort = 1;
  sOspiManagerCfg.DQSPort = 1;
  sOspiManagerCfg.NCSPort = 1;
  sOspiManagerCfg.IOLowPort = HAL_OSPIM_IOPORT_2_LOW;
  sOspiManagerCfg.IOHighPort = HAL_OSPIM_IOPORT_2_HIGH;
  sOspiManagerCfg.Req2AckTime = 1;
  if (HAL_OSPIM_Config(&hospi1, &sOspiManagerCfg, HAL_OSPI_TIMEOUT_DEFAULT_VALUE) != HAL_OK)
  {
    Error_Handler();
  }
  sHyperBusCfg.RWRecoveryTime = 0;
  sHyperBusCfg.AccessTime = 0;
  sHyperBusCfg.WriteZeroLatency = HAL_OSPI_NO_LATENCY_ON_WRITE;
  sHyperBusCfg.LatencyMode = HAL_OSPI_VARIABLE_LATENCY;
  if (HAL_OSPI_HyperbusCfg(&hospi1, &sHyperBusCfg, HAL_OSPI_TIMEOUT_DEFAULT_VALUE) != HAL_OK)
  {
    Error_Handler();
  }
  HAL_OSPI_DLYB_Cfg_Struct.Units = 0;
  HAL_OSPI_DLYB_Cfg_Struct.PhaseSel = 0;
  if (HAL_OSPI_DLYB_SetConfig(&hospi1, &HAL_OSPI_DLYB_Cfg_Struct) != HAL_OK)
  {
    Error_Handler();
  }

}

static void MX_OCTOSPI2_Init(void)
{

  OSPIM_CfgTypeDef sOspiManagerCfg = {0};
  OSPI_HyperbusCfgTypeDef sHyperBusCfg = {0};
  HAL_OSPI_DLYB_CfgTypeDef HAL_OSPI_DLYB_Cfg_Struct = {0};

  /* OCTOSPI2 parameter configuration*/
  hospi2.Instance = OCTOSPI2;
  hospi2.Init.FifoThreshold = 1;
  hospi2.Init.DualQuad = HAL_OSPI_DUALQUAD_DISABLE;
  hospi2.Init.MemoryType = HAL_OSPI_MEMTYPE_HYPERBUS;
  hospi2.Init.DeviceSize = 32;
  hospi2.Init.ChipSelectHighTime = 1;
  hospi2.Init.FreeRunningClock = HAL_OSPI_FREERUNCLK_DISABLE;
  hospi2.Init.ClockMode = HAL_OSPI_CLOCK_MODE_0;
  hospi2.Init.WrapSize = HAL_OSPI_WRAP_NOT_SUPPORTED;
  hospi2.Init.ClockPrescaler = 1;
  hospi2.Init.SampleShifting = HAL_OSPI_SAMPLE_SHIFTING_NONE;
  hospi2.Init.DelayHoldQuarterCycle = HAL_OSPI_DHQC_DISABLE;
  hospi2.Init.ChipSelectBoundary = 0;
  hospi2.Init.DelayBlockBypass = HAL_OSPI_DELAY_BLOCK_BYPASSED;
  hospi2.Init.MaxTran = 0;
  hospi2.Init.Refresh = 0;
  if (HAL_OSPI_Init(&hospi2) != HAL_OK)
  {
    Error_Handler();
  }
  sOspiManagerCfg.ClkPort = 1;
  sOspiManagerCfg.DQSPort = 1;
  sOspiManagerCfg.NCSPort = 2;
  sOspiManagerCfg.IOLowPort = HAL_OSPIM_IOPORT_2_LOW;
  sOspiManagerCfg.IOHighPort = HAL_OSPIM_IOPORT_2_HIGH;
  sOspiManagerCfg.Req2AckTime = 1;
  if (HAL_OSPIM_Config(&hospi2, &sOspiManagerCfg, HAL_OSPI_TIMEOUT_DEFAULT_VALUE) != HAL_OK)
  {
    Error_Handler();
  }
  sHyperBusCfg.RWRecoveryTime = 0;
  sHyperBusCfg.AccessTime = 0;
  sHyperBusCfg.WriteZeroLatency = HAL_OSPI_NO_LATENCY_ON_WRITE;
  sHyperBusCfg.LatencyMode = HAL_OSPI_VARIABLE_LATENCY;
  if (HAL_OSPI_HyperbusCfg(&hospi2, &sHyperBusCfg, HAL_OSPI_TIMEOUT_DEFAULT_VALUE) != HAL_OK)
  {
    Error_Handler();
  }
  HAL_OSPI_DLYB_Cfg_Struct.Units = 0;
  HAL_OSPI_DLYB_Cfg_Struct.PhaseSel = 0;
  if (HAL_OSPI_DLYB_SetConfig(&hospi2, &HAL_OSPI_DLYB_Cfg_Struct) != HAL_OK)
  {
    Error_Handler();
  }

}

static void MX_RTC_Init(void)
{

  RTC_PrivilegeStateTypeDef privilegeState = {0};
  RTC_TimeTypeDef sTime = {0};
  RTC_DateTypeDef sDate = {0};

  /** Initialize RTC Only
  */
  hrtc.Instance = RTC;
  hrtc.Init.HourFormat = RTC_HOURFORMAT_24;
  hrtc.Init.AsynchPrediv = 127;
  hrtc.Init.SynchPrediv = 255;
  hrtc.Init.OutPut = RTC_OUTPUT_DISABLE;
  hrtc.Init.OutPutRemap = RTC_OUTPUT_REMAP_NONE;
  hrtc.Init.OutPutPolarity = RTC_OUTPUT_POLARITY_HIGH;
  hrtc.Init.OutPutType = RTC_OUTPUT_TYPE_OPENDRAIN;
  hrtc.Init.OutPutPullUp = RTC_OUTPUT_PULLUP_NONE;
  hrtc.Init.BinMode = RTC_BINARY_NONE;
  if (HAL_RTC_Init(&hrtc) != HAL_OK)
  {
    Error_Handler();
  }
  privilegeState.rtcPrivilegeFull = RTC_PRIVILEGE_FULL_NO;
  privilegeState.backupRegisterPrivZone = RTC_PRIVILEGE_BKUP_ZONE_NONE;
  privilegeState.backupRegisterStartZone2 = RTC_BKP_DR0;
  privilegeState.backupRegisterStartZone3 = RTC_BKP_DR0;
  if (HAL_RTCEx_PrivilegeModeSet(&hrtc, &privilegeState) != HAL_OK)
  {
    Error_Handler();
  }

  /** Initialize RTC and set the Time and Date
  */
  sTime.Hours = 0x0;
  sTime.Minutes = 0x0;
  sTime.Seconds = 0x0;
  sTime.DayLightSaving = RTC_DAYLIGHTSAVING_NONE;
  sTime.StoreOperation = RTC_STOREOPERATION_RESET;
  if (HAL_RTC_SetTime(&hrtc, &sTime, RTC_FORMAT_BCD) != HAL_OK)
  {
    Error_Handler();
  }
  sDate.WeekDay = RTC_WEEKDAY_MONDAY;
  sDate.Month = RTC_MONTH_JANUARY;
  sDate.Date = 0x1;
  sDate.Year = 0x0;

  if (HAL_RTC_SetDate(&hrtc, &sDate, RTC_FORMAT_BCD) != HAL_OK)
  {
    Error_Handler();
  }

}

static void MX_SPI1_Init(void)
{

  SPI_AutonomousModeConfTypeDef HAL_SPI_AutonomousMode_Cfg_Struct = {0};

  /* SPI1 parameter configuration*/
  hspi1.Instance = SPI1;
  hspi1.Init.Mode = SPI_MODE_MASTER;
  hspi1.Init.Direction = SPI_DIRECTION_2LINES;
  hspi1.Init.DataSize = SPI_DATASIZE_4BIT;
  hspi1.Init.CLKPolarity = SPI_POLARITY_LOW;
  hspi1.Init.CLKPhase = SPI_PHASE_1EDGE;
  hspi1.Init.NSS = SPI_NSS_HARD_OUTPUT;
  hspi1.Init.BaudRatePrescaler = SPI_BAUDRATEPRESCALER_2;
  hspi1.Init.FirstBit = SPI_FIRSTBIT_MSB;
  hspi1.Init.TIMode = SPI_TIMODE_DISABLE;
  hspi1.Init.CRCCalculation = SPI_CRCCALCULATION_DISABLE;
  hspi1.Init.CRCPolynomial = 0x7;
  hspi1.Init.NSSPMode = SPI_NSS_PULSE_ENABLE;
  hspi1.Init.NSSPolarity = SPI_NSS_POLARITY_LOW;
  hspi1.Init.FifoThreshold = SPI_FIFO_THRESHOLD_01DATA;
  hspi1.Init.MasterSSIdleness = SPI_MASTER_SS_IDLENESS_00CYCLE;
  hspi1.Init.MasterInterDataIdleness = SPI_MASTER_INTERDATA_IDLENESS_00CYCLE;
  hspi1.Init.MasterReceiverAutoSusp = SPI_MASTER_RX_AUTOSUSP_DISABLE;
  hspi1.Init.MasterKeepIOState = SPI_MASTER_KEEP_IO_STATE_DISABLE;
  hspi1.Init.IOSwap = SPI_IO_SWAP_DISABLE;
  hspi1.Init.ReadyMasterManagement = SPI_RDY_MASTER_MANAGEMENT_INTERNALLY;
  hspi1.Init.ReadyPolarity = SPI_RDY_POLARITY_HIGH;
  if (HAL_SPI_Init(&hspi1) != HAL_OK)
  {
    Error_Handler();
  }
  HAL_SPI_AutonomousMode_Cfg_Struct.TriggerState = SPI_AUTO_MODE_DISABLE;
  HAL_SPI_AutonomousMode_Cfg_Struct.TriggerSelection = SPI_GRP1_GPDMA_CH0_TCF_TRG;
  HAL_SPI_AutonomousMode_Cfg_Struct.TriggerPolarity = SPI_TRIG_POLARITY_RISING;
  if (HAL_SPIEx_SetConfigAutonomousMode(&hspi1, &HAL_SPI_AutonomousMode_Cfg_Struct) != HAL_OK)
  {
    Error_Handler();
  }

}

static void MX_GPIO_Init(void)
{
  GPIO_InitTypeDef GPIO_InitStruct = {0};

  /* GPIO Ports Clock Enable */
  __HAL_RCC_GPIOB_CLK_ENABLE();
  __HAL_RCC_GPIOG_CLK_ENABLE();
  __HAL_RCC_GPIOD_CLK_ENABLE();
  __HAL_RCC_GPIOC_CLK_ENABLE();
  __HAL_RCC_GPIOA_CLK_ENABLE();
  __HAL_RCC_GPIOJ_CLK_ENABLE();
  __HAL_RCC_GPIOH_CLK_ENABLE();
  __HAL_RCC_GPIOI_CLK_ENABLE();
  __HAL_RCC_GPIOF_CLK_ENABLE();
  __HAL_RCC_GPIOE_CLK_ENABLE();

  /*Configure GPIO pin Output Level */
  HAL_GPIO_WritePin(AVDDEN_GPIO_Port, AVDDEN_Pin, GPIO_PIN_RESET);

  /*Configure GPIO pin Output Level */
  HAL_GPIO_WritePin(GPIOD, SDMMC_EN_Pin|LRA_EN_Pin, GPIO_PIN_RESET);

  /*Configure GPIO pin Output Level */
  HAL_GPIO_WritePin(GPIOB, GPIO3_Pin|PWR_ENCHG_Pin, GPIO_PIN_RESET);

  /*Configure GPIO pin Output Level */
  HAL_GPIO_WritePin(GPIOJ, GNSS_RST_Pin|TP_RST_Pin|GNSS_WAKEUP_Pin, GPIO_PIN_RESET);

  /*Configure GPIO pin Output Level */
  HAL_GPIO_WritePin(FLASH_RST_GPIO_Port, FLASH_RST_Pin, GPIO_PIN_RESET);

  /*Configure GPIO pin Output Level */
  HAL_GPIO_WritePin(DISPLAY_RST_GPIO_Port, DISPLAY_RST_Pin, GPIO_PIN_RESET);

  /*Configure GPIO pin Output Level */
  HAL_GPIO_WritePin(TOUCH_RST_GPIO_Port, TOUCH_RST_Pin, GPIO_PIN_RESET);

  /*Configure GPIO pins : DISPLAY_SWIRE_IN_Pin DISPLAY_SWIRE_OUT_Pin */
  GPIO_InitStruct.Pin = DISPLAY_SWIRE_IN_Pin|DISPLAY_SWIRE_OUT_Pin;
  GPIO_InitStruct.Mode = GPIO_MODE_INPUT;
  GPIO_InitStruct.Pull = GPIO_NOPULL;
  HAL_GPIO_Init(GPIOG, &GPIO_InitStruct);

  /*Configure GPIO pin : AVDDEN_Pin */
  GPIO_InitStruct.Pin = AVDDEN_Pin;
  GPIO_InitStruct.Mode = GPIO_MODE_OUTPUT_PP;
  GPIO_InitStruct.Pull = GPIO_PULLDOWN;
  GPIO_InitStruct.Speed = GPIO_SPEED_FREQ_LOW;
  HAL_GPIO_Init(AVDDEN_GPIO_Port, &GPIO_InitStruct);

  /*Configure GPIO pin : SDMMC_EN_Pin */
  GPIO_InitStruct.Pin = SDMMC_EN_Pin;
  GPIO_InitStruct.Mode = GPIO_MODE_OUTPUT_PP;
  GPIO_InitStruct.Pull = GPIO_NOPULL;
  GPIO_InitStruct.Speed = GPIO_SPEED_FREQ_LOW;
  HAL_GPIO_Init(SDMMC_EN_GPIO_Port, &GPIO_InitStruct);

  /*Configure GPIO pins : SDMMC1_CD_Pin PWR_INT_Pin */
  GPIO_InitStruct.Pin = SDMMC1_CD_Pin|PWR_INT_Pin;
  GPIO_InitStruct.Mode = GPIO_MODE_INPUT;
  GPIO_InitStruct.Pull = GPIO_PULLUP;
  HAL_GPIO_Init(GPIOD, &GPIO_InitStruct);

  /*Configure GPIO pins : PC10 PC8 PC11 PC12
                           PC9 */
  GPIO_InitStruct.Pin = GPIO_PIN_10|GPIO_PIN_8|GPIO_PIN_11|GPIO_PIN_12
                          |GPIO_PIN_9;
  GPIO_InitStruct.Mode = GPIO_MODE_AF_PP;
  GPIO_InitStruct.Pull = GPIO_NOPULL;
  GPIO_InitStruct.Speed = GPIO_SPEED_FREQ_HIGH;
  GPIO_InitStruct.Alternate = GPIO_AF12_SDMMC1;
  HAL_GPIO_Init(GPIOC, &GPIO_InitStruct);

  /*Configure GPIO pins : GPIO3_Pin PWR_ENCHG_Pin */
  GPIO_InitStruct.Pin = GPIO3_Pin|PWR_ENCHG_Pin;
  GPIO_InitStruct.Mode = GPIO_MODE_OUTPUT_PP;
  GPIO_InitStruct.Pull = GPIO_PULLDOWN;
  GPIO_InitStruct.Speed = GPIO_SPEED_FREQ_LOW;
  HAL_GPIO_Init(GPIOB, &GPIO_InitStruct);

  /*Configure GPIO pin : PD2 */
  GPIO_InitStruct.Pin = GPIO_PIN_2;
  GPIO_InitStruct.Mode = GPIO_MODE_AF_PP;
  GPIO_InitStruct.Pull = GPIO_NOPULL;
  GPIO_InitStruct.Speed = GPIO_SPEED_FREQ_HIGH;
  GPIO_InitStruct.Alternate = GPIO_AF12_SDMMC1;
  HAL_GPIO_Init(GPIOD, &GPIO_InitStruct);

  /*Configure GPIO pins : PA12 PA11 */
  GPIO_InitStruct.Pin = GPIO_PIN_12|GPIO_PIN_11;
  GPIO_InitStruct.Mode = GPIO_MODE_AF_PP;
  GPIO_InitStruct.Pull = GPIO_NOPULL;
  GPIO_InitStruct.Speed = GPIO_SPEED_FREQ_LOW;
  HAL_GPIO_Init(GPIOA, &GPIO_InitStruct);

  /*Configure GPIO pin : BT_INT2_Pin */
  GPIO_InitStruct.Pin = BT_INT2_Pin;
  GPIO_InitStruct.Mode = GPIO_MODE_INPUT;
  GPIO_InitStruct.Pull = GPIO_PULLDOWN;
  HAL_GPIO_Init(BT_INT2_GPIO_Port, &GPIO_InitStruct);

  /*Configure GPIO pin : PB8 */
  GPIO_InitStruct.Pin = GPIO_PIN_8;
  GPIO_InitStruct.Mode = GPIO_MODE_AF_PP;
  GPIO_InitStruct.Pull = GPIO_NOPULL;
  GPIO_InitStruct.Speed = GPIO_SPEED_FREQ_HIGH;
  GPIO_InitStruct.Alternate = GPIO_AF8_SDMMC1;
  HAL_GPIO_Init(GPIOB, &GPIO_InitStruct);

  /*Configure GPIO pins : GPIO2_Pin GPIO1_Pin */
  GPIO_InitStruct.Pin = GPIO2_Pin|GPIO1_Pin;
  GPIO_InitStruct.Mode = GPIO_MODE_INPUT;
  GPIO_InitStruct.Pull = GPIO_PULLDOWN;
  HAL_GPIO_Init(GPIOD, &GPIO_InitStruct);

  /*Configure GPIO pin : BT_INT1_Pin */
  GPIO_InitStruct.Pin = BT_INT1_Pin;
  GPIO_InitStruct.Mode = GPIO_MODE_IT_RISING;
  GPIO_InitStruct.Pull = GPIO_PULLDOWN;
  HAL_GPIO_Init(BT_INT1_GPIO_Port, &GPIO_InitStruct);

  /*Configure GPIO pins : GNSS_RST_Pin TP_RST_Pin */
  GPIO_InitStruct.Pin = GNSS_RST_Pin|TP_RST_Pin;
  GPIO_InitStruct.Mode = GPIO_MODE_OUTPUT_PP;
  GPIO_InitStruct.Pull = GPIO_PULLUP;
  GPIO_InitStruct.Speed = GPIO_SPEED_FREQ_LOW;
  HAL_GPIO_Init(GPIOJ, &GPIO_InitStruct);

  /*Configure GPIO pin : GNSS_PPS_Pin */
  GPIO_InitStruct.Pin = GNSS_PPS_Pin;
  GPIO_InitStruct.Mode = GPIO_MODE_IT_RISING;
  GPIO_InitStruct.Pull = GPIO_NOPULL;
  HAL_GPIO_Init(GNSS_PPS_GPIO_Port, &GPIO_InitStruct);

  /*Configure GPIO pin : GNSS_WAKEUP_Pin */
  GPIO_InitStruct.Pin = GNSS_WAKEUP_Pin;
  GPIO_InitStruct.Mode = GPIO_MODE_OUTPUT_PP;
  GPIO_InitStruct.Pull = GPIO_NOPULL;
  GPIO_InitStruct.Speed = GPIO_SPEED_FREQ_LOW;
  HAL_GPIO_Init(GNSS_WAKEUP_GPIO_Port, &GPIO_InitStruct);

  /*Configure GPIO pin : TP_INT_Pin */
  GPIO_InitStruct.Pin = TP_INT_Pin;
  GPIO_InitStruct.Mode = GPIO_MODE_IT_FALLING;
  GPIO_InitStruct.Pull = GPIO_PULLUP;
  HAL_GPIO_Init(TP_INT_GPIO_Port, &GPIO_InitStruct);

  /*Configure GPIO pin : FLASH_RST_Pin */
  GPIO_InitStruct.Pin = FLASH_RST_Pin;
  GPIO_InitStruct.Mode = GPIO_MODE_OUTPUT_PP;
  GPIO_InitStruct.Pull = GPIO_PULLUP;
  GPIO_InitStruct.Speed = GPIO_SPEED_FREQ_LOW;
  HAL_GPIO_Init(FLASH_RST_GPIO_Port, &GPIO_InitStruct);

  /*Configure GPIO pin : FLASH_INT_Pin */
  GPIO_InitStruct.Pin = FLASH_INT_Pin;
  GPIO_InitStruct.Mode = GPIO_MODE_IT_FALLING;
  GPIO_InitStruct.Pull = GPIO_PULLUP;
  HAL_GPIO_Init(FLASH_INT_GPIO_Port, &GPIO_InitStruct);

  /*Configure GPIO pin : FLASH_RSTO_Pin */
  GPIO_InitStruct.Pin = FLASH_RSTO_Pin;
  GPIO_InitStruct.Mode = GPIO_MODE_INPUT;
  GPIO_InitStruct.Pull = GPIO_PULLUP;
  HAL_GPIO_Init(FLASH_RSTO_GPIO_Port, &GPIO_InitStruct);

  /*Configure GPIO pin : DISPLAY_RST_Pin */
  GPIO_InitStruct.Pin = DISPLAY_RST_Pin;
  GPIO_InitStruct.Mode = GPIO_MODE_OUTPUT_PP;
  GPIO_InitStruct.Pull = GPIO_PULLUP;
  GPIO_InitStruct.Speed = GPIO_SPEED_FREQ_LOW;
  HAL_GPIO_Init(DISPLAY_RST_GPIO_Port, &GPIO_InitStruct);

  /*Configure GPIO pin : ALS_INT_Pin */
  GPIO_InitStruct.Pin = ALS_INT_Pin;
  GPIO_InitStruct.Mode = GPIO_MODE_INPUT;
  GPIO_InitStruct.Pull = GPIO_PULLUP;
  HAL_GPIO_Init(ALS_INT_GPIO_Port, &GPIO_InitStruct);

  /*Configure GPIO pin : TOUCH_INT_Pin */
  GPIO_InitStruct.Pin = TOUCH_INT_Pin;
  GPIO_InitStruct.Mode = GPIO_MODE_IT_FALLING;
  GPIO_InitStruct.Pull = GPIO_PULLUP;
  HAL_GPIO_Init(TOUCH_INT_GPIO_Port, &GPIO_InitStruct);

  /*Configure GPIO pin : TOUCH_RST_Pin */
  GPIO_InitStruct.Pin = TOUCH_RST_Pin;
  GPIO_InitStruct.Mode = GPIO_MODE_OUTPUT_PP;
  GPIO_InitStruct.Pull = GPIO_PULLUP;
  GPIO_InitStruct.Speed = GPIO_SPEED_FREQ_LOW;
  HAL_GPIO_Init(TOUCH_RST_GPIO_Port, &GPIO_InitStruct);

  /*Configure GPIO pin : HR_INT_Pin */
  GPIO_InitStruct.Pin = HR_INT_Pin;
  GPIO_InitStruct.Mode = GPIO_MODE_IT_FALLING;
  GPIO_InitStruct.Pull = GPIO_PULLUP;
  HAL_GPIO_Init(HR_INT_GPIO_Port, &GPIO_InitStruct);

  /*Configure GPIO pin : LRA_EN_Pin */
  GPIO_InitStruct.Pin = LRA_EN_Pin;
  GPIO_InitStruct.Mode = GPIO_MODE_OUTPUT_PP;
  GPIO_InitStruct.Pull = GPIO_PULLDOWN;
  GPIO_InitStruct.Speed = GPIO_SPEED_FREQ_LOW;
  HAL_GPIO_Init(LRA_EN_GPIO_Port, &GPIO_InitStruct);

  /*Configure GPIO pin : MAG_INT_Pin */
  GPIO_InitStruct.Pin = MAG_INT_Pin;
  GPIO_InitStruct.Mode = GPIO_MODE_IT_FALLING;
  GPIO_InitStruct.Pull = GPIO_PULLUP;
  HAL_GPIO_Init(MAG_INT_GPIO_Port, &GPIO_InitStruct);

  /*Configure GPIO pin : IMU_INT1_Pin */
  GPIO_InitStruct.Pin = IMU_INT1_Pin;
  GPIO_InitStruct.Mode = GPIO_MODE_IT_RISING;
  GPIO_InitStruct.Pull = GPIO_NOPULL;
  HAL_GPIO_Init(IMU_INT1_GPIO_Port, &GPIO_InitStruct);

  /*Configure GPIO pin : IMU_INT2_Pin */
  GPIO_InitStruct.Pin = IMU_INT2_Pin;
  GPIO_InitStruct.Mode = GPIO_MODE_INPUT;
  GPIO_InitStruct.Pull = GPIO_NOPULL;
  HAL_GPIO_Init(IMU_INT2_GPIO_Port, &GPIO_InitStruct);

}

void HAL_TIM_PeriodElapsedCallback(TIM_HandleTypeDef *htim)
{
  if (htim->Instance == TIM6) {
    HAL_IncTick();
  }
}

void Error_Handler(void)
{
  __disable_irq();
  while (1)
  {
  }
}
